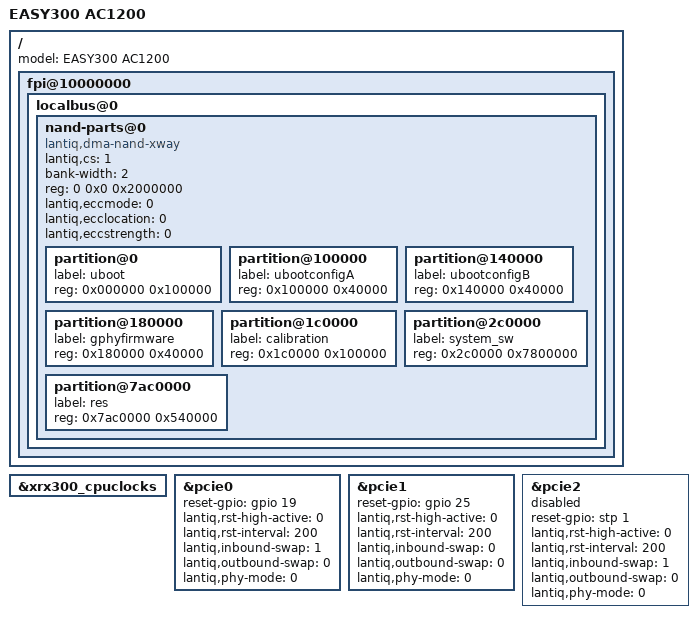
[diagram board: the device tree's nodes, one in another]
/dts-v1/;


/include/ "EASY300_AC1200.dtsi"

/ {

	model = "EASY300 AC1200";

	fpi@10000000 {
		localbus@0 {
			ranges = <0 0 0x4000000 0x3ffffff>;
			nand-parts@0 {
				compatible = "lantiq,dma-nand-xway";
                                lantiq,cs = <1>;
                                bank-width = <2>;
                                reg = <0 0x0 0x2000000>;
                                #address-cells = <1>;
                                #size-cells = <1>;
                                lantiq,eccmode = <0>;
                                lantiq,ecclocation = <0>;
                                lantiq,eccstrength = <0>;

				partition@0 {
                                        label = "uboot";
                                        reg = <0x000000 0x100000>;
                                };

                                partition@100000 {
                                        label = "ubootconfigA";
                                        reg = <0x100000 0x40000>;
                                };

                                partition@140000 {
                                        label = "ubootconfigB";
                                        reg = <0x140000 0x40000>;
                                };

                                partition@180000 {
                                        label = "gphyfirmware";
                                        reg = <0x180000 0x40000>;
                                };

                                partition@1c0000 {
                                        label = "calibration";
                                        reg = <0x1c0000 0x100000>;
                                };

                                partition@2c0000 {
                                        label = "system_sw";
                                        reg = <0x2c0000 0x7800000>;
                                };

                                partition@7ac0000 {
                                        label = "res";
                                        reg = <0x7ac0000 0x540000>;
                                };
			};
		};
	};
};

&xrx300_cpuclocks {
	status = "okay";
};

&pcie0 {
	status = "ok";
	reset-gpio = <&gpio 19 0>;
	lantiq,rst-high-active = <0>; /* 0 - low activ, 1 -- high active */
	lantiq,rst-interval = <200>; /* in mili-seconds, up to 500 ms*/
	lantiq,inbound-swap = <1>; /* 0 -- no swap, 1 -- swap */
	lantiq,outbound-swap = <0>; /* 0 -- no swap, 1 -- swap */
	lantiq,phy-mode = <0>; /* 0 -36Mhz, 1 - 36MHzSSC, 2 - 25Mhz, 3 - 25MHzSSC, 4 - 100MHz */
};

&pcie1 {
	status = "ok";
	reset-gpio = <&gpio 25 0>;
	lantiq,rst-high-active = <0>; /* 0 - low activ, 1 -- high active */
	lantiq,rst-interval = <200>; /* in mili-seconds, up to 500 ms*/
	lantiq,inbound-swap = <0>; /* 0 -- no swap, 1 -- swap */
	lantiq,outbound-swap = <0>; /* 0 -- no swap, 1 -- swap */
	lantiq,phy-mode = <0>; /* 0 -36Mhz, 1 - 36MHzSSC, 2 - 25Mhz, 3 - 25MHzSSC, 4 - 100MHz */
};

&pcie2 {
        status = "disabled";
        reset-gpio = <&stp 1 0>;
        lantiq,rst-high-active = <0>; /* 0 - low activ, 1 -- high active */
        lantiq,rst-interval = <200>; /* in mili-seconds, up to 500 ms*/
        lantiq,inbound-swap = <1>; /* 0 -- no swap, 1 -- swap */
        lantiq,outbound-swap = <0>; /* 0 -- no swap, 1 -- swap */
        lantiq,phy-mode = <0>; /* 0 -36Mhz, 1 - 36MHzSSC, 2 - 25Mhz, 3 - 25MHzSSC, 4 - 100MHz */
};
